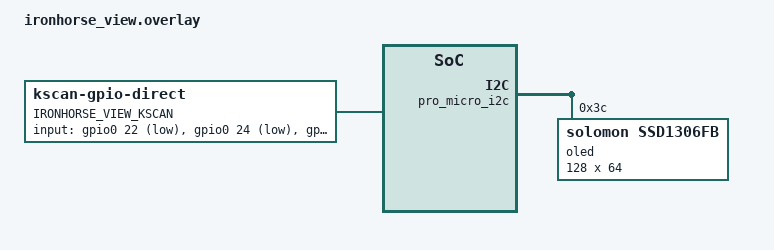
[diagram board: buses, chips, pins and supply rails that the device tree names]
#include <dt-bindings/zmk/matrix_transform.h>
#include "../ironhorse/ironhorse_view_transform.dtsi"

/ {
    chosen {
        zephyr,display = &oled;
        zmk,kscan = &ironhorse_view_kscan;
        zmk,matrix_transform = &ironhorse_view_transform;
    };

    ironhorse_view_kscan: kscan {
        compatible = "zmk,kscan-gpio-direct";
        label = "IRONHORSE_VIEW_KSCAN";
        wakeup-source;
        debounce-press-ms = <5>;
        debounce-release-ms = <20>;
        input-gpios
            = <&gpio0 22 (GPIO_ACTIVE_LOW | GPIO_PULL_UP)>
            , <&gpio0 24 (GPIO_ACTIVE_LOW | GPIO_PULL_UP)>
            , <&gpio1 0 (GPIO_ACTIVE_LOW | GPIO_PULL_UP)>
            , <&gpio0 11 (GPIO_ACTIVE_LOW | GPIO_PULL_UP)>
            , <&gpio1 4 (GPIO_ACTIVE_LOW | GPIO_PULL_UP)>
            , <&gpio1 15 (GPIO_ACTIVE_LOW | GPIO_PULL_UP)>
            , <&gpio0 2 (GPIO_ACTIVE_LOW | GPIO_PULL_UP)>
            , <&gpio0 29 (GPIO_ACTIVE_LOW | GPIO_PULL_UP)>
            , <&gpio0 31 (GPIO_ACTIVE_LOW | GPIO_PULL_UP)>
            ;
    };

    ironhorse_view_transform: matrix_transform {
        compatible = "zmk,matrix-transform";
        columns = <21>;
        rows = <4>;
        col-offset = <12>;
        map = <IRONHORSE_VIEW_TRANSFORM_MAP>;
    };
};

&pro_micro_i2c {
    status = "okay";

    oled: ssd1306@3c {
        compatible = "solomon,ssd1306fb";
        reg = <0x3c>;
        width = <128>;
        height = <64>;
        segment-offset = <0>;
        page-offset = <0>;
        display-offset = <0>;
        multiplex-ratio = <63>;
        segment-remap;
        com-invdir;
        com-sequential;
        inversion-on;
        prechargep = <0x22>;
    };
};

&uicr {
    nfct-pins-as-gpios;
};
